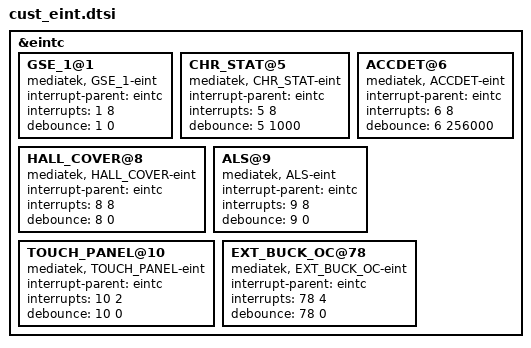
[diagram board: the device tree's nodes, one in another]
/*
 * Generated by MTK SP Drv_CodeGen Version 03.13.6  for MT6753. Copyright MediaTek Inc. (C) 2013.
 * Sun Sep  4 11:34:49 2016
 * Do Not Modify the File.
 */

/*************************
 * EINT DTSI File
*************************/

&eintc {
	GSE_1@1 {
		compatible = "mediatek, GSE_1-eint";
		interrupt-parent = <&eintc>;
		interrupts = <1 8>;
		debounce = <1 0>;
	};

	CHR_STAT@5 {
		compatible = "mediatek, CHR_STAT-eint";
		interrupt-parent = <&eintc>;
		interrupts = <5 8>;
		debounce = <5 1000>;
	};

	ACCDET@6 {
		compatible = "mediatek, ACCDET-eint";
		interrupt-parent = <&eintc>;
		interrupts = <6 8>;
		debounce = <6 256000>;
	};

	HALL_COVER@8 {
		compatible = "mediatek, HALL_COVER-eint";
		interrupt-parent = <&eintc>;
		interrupts = <8 8>;
		debounce = <8 0>;
	};

	ALS@9 {
		compatible = "mediatek, ALS-eint";
		interrupt-parent = <&eintc>;
		interrupts = <9 8>;
		debounce = <9 0>;
	};

	TOUCH_PANEL@10 {
		compatible = "mediatek, TOUCH_PANEL-eint";
		interrupt-parent = <&eintc>;
		interrupts = <10 2>;
		debounce = <10 0>;
	};

	EXT_BUCK_OC@78 {
		compatible = "mediatek, EXT_BUCK_OC-eint";
		interrupt-parent = <&eintc>;
		interrupts = <78 4>;
		debounce = <78 0>;
	};

};
